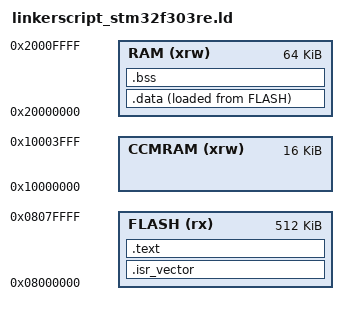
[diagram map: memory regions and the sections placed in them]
ENTRY(Reset_Handler)

_estack = ORIGIN(RAM) + LENGTH(RAM);    /* end of RAM */

_Min_Heap_Size = 0x200;      /* required amount of heap  */
_Min_Stack_Size = 0x400; /* required amount of stack */

MEMORY
{
RAM (xrw)      : ORIGIN = 0x20000000, LENGTH = 64K
CCMRAM (xrw)      : ORIGIN = 0x10000000, LENGTH = 16K
FLASH (rx)      : ORIGIN = 0x08000000, LENGTH = 512K
}


SECTIONS 
{
    .isr_vector :
    {
        . = ALIGN(4);
        KEEP(*(.isr_vector))
        . = ALIGN(4);
    }> FLASH

    .text :
    {
        . = ALIGN(4);
        *(.text)
        *(.text.*)
        *(.rodata)
        *(.rodata.*)
        . = ALIGN(4);
    }> FLASH

    _sidata = LOADADDR(.data);
    
    .data :
    {
        . = ALIGN(4);
        _sdata = .;
        *(.data)
        *(.data.*)
        . = ALIGN(4);
        _edata = .;
    }> RAM AT> FLASH

    .bss :
    {
        . = ALIGN(4);
        _sbss = .;
        *(.bss)
        *(.bss.*)
        . = ALIGN(4);
        _ebss = .;
    }> RAM
}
